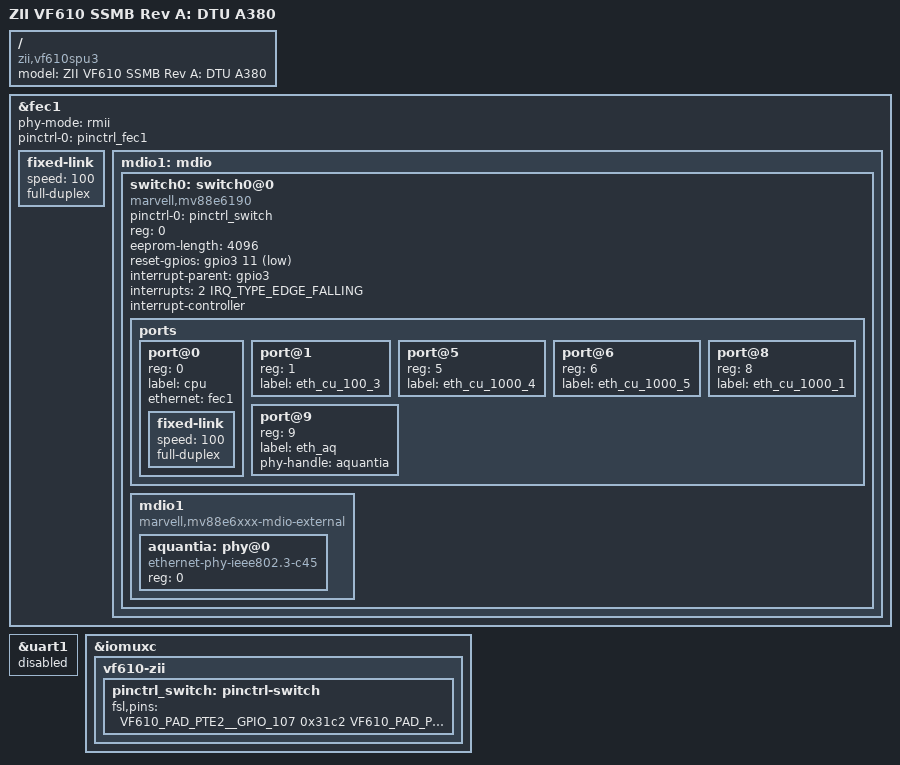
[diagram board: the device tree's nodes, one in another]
/*
 * Copyright (C) 2015, 2016 Zodiac Inflight Innovations
 *
 * Based on an original 'vf610-twr.dts' which is Copyright 2015,
 * Freescale Semiconductor, Inc.
 *
 * This file is dual-licensed: you can use it either under the terms
 * of the GPL or the X11 license, at your option. Note that this dual
 * licensing only applies to this file, and not this project as a
 * whole.
 *
 *  a) This file is free software; you can redistribute it and/or
 *     modify it under the terms of the GNU General Public License
 *     version 2 as published by the Free Software Foundation.
 *
 *     This file is distributed in the hope that it will be useful
 *     but WITHOUT ANY WARRANTY; without even the implied warranty of
 *     MERCHANTABILITY or FITNESS FOR A PARTICULAR PURPOSE.  See the
 *     GNU General Public License for more details.
 *
 * Or, alternatively
 *
 *  b) Permission is hereby granted, free of charge, to any person
 *     obtaining a copy of this software and associated documentation
 *     files (the "Software"), to deal in the Software without
 *     restriction, including without limitation the rights to use
 *     copy, modify, merge, publish, distribute, sublicense, and/or
 *     sell copies of the Software, and to permit persons to whom the
 *     Software is furnished to do so, subject to the following
 *     conditions:
 *
 *     The above copyright notice and this permission notice shall be
 *     included in all copies or substantial portions of the Software.
 *
 *     THE SOFTWARE IS PROVIDED , WITHOUT WARRANTY OF ANY KIND
 *     EXPRESS OR IMPLIED, INCLUDING BUT NOT LIMITED TO THE WARRANTIES
 *     OF MERCHANTABILITY, FITNESS FOR A PARTICULAR PURPOSE AND
 *     NONINFRINGEMENT. IN NO EVENT SHALL THE AUTHORS OR COPYRIGHT
 *     HOLDERS BE LIABLE FOR ANY CLAIM, DAMAGES OR OTHER LIABILITY
 *     WHETHER IN AN ACTION OF CONTRACT, TORT OR OTHERWISE, ARISING
 *     FROM, OUT OF OR IN CONNECTION WITH THE SOFTWARE OR THE USE OR
 *     OTHER DEALINGS IN THE SOFTWARE.
 */

/dts-v1/;
#include "vf610.dtsi"
#include "vf610-zii-ssmb.dtsi"


/ {
	model = "ZII VF610 SSMB Rev A: DTU A380";
	compatible = "zii,vf610spu3", "fsl,vf610";
};


&fec1 {
	phy-mode = "rmii";
	pinctrl-names = "default";
	pinctrl-0 = <&pinctrl_fec1>;
	status = "okay";

	fixed-link {
		   speed = <100>;
		   full-duplex;
	};

	mdio1: mdio {
		#address-cells = <1>;
		#size-cells = <0>;
		status = "okay";

		switch0: switch0@0 {
			compatible = "marvell,mv88e6190";
			pinctrl-0 = <&pinctrl_switch>;
			pinctrl-names = "default";
			#address-cells = <1>;
			#size-cells = <0>;
			reg = <0>;
			eeprom-length = <4096>;
			reset-gpios = <&gpio3 11 GPIO_ACTIVE_LOW>;
			interrupt-parent = <&gpio3>;
			interrupts = <2 IRQ_TYPE_EDGE_FALLING>;
			interrupt-controller;

			ports {
				#address-cells = <1>;
				#size-cells = <0>;
				port@0 {
					reg = <0>;
					label = "cpu";
					ethernet = <&fec1>;
					fixed-link {
						speed = <100>;
						full-duplex;
					};
				};
				port@1 {
					reg = <1>;
					label = "eth_cu_100_3";
				};

				port@5 {
					reg = <5>;
					label = "eth_cu_1000_4";
				};

				port@6 {
					reg = <6>;
					label = "eth_cu_1000_5";
				};

				/* hardware-disabled in flavour of port9 */
				//port@7 {
				//	reg = <7>;
				//	label = "eth_cu_100_2";
				//};

				port@8 {
					reg = <8>;
					label = "eth_cu_1000_1";
				};

				port@9 {
					reg = <9>;
					label = "eth_aq";
					phy-handle = <&aquantia>;
				};
			};

			mdio1 {
				compatible = "marvell,mv88e6xxx-mdio-external";
				#address-cells = <1>;
				#size-cells = <0>;

				aquantia: phy@0 {
					compatible = "ethernet-phy-ieee802.3-c45";
					reg = <0>;
				};
			};
		};
	};
};

/* UART1 pins are used as GPIO */
&uart1 {
	status = "disabled";
};

&iomuxc {
	vf610-zii {
		pinctrl_switch: pinctrl-switch {
			fsl,pins = <
				/* switch reset */
				VF610_PAD_PTE2__GPIO_107	0x31c2
				/* switch interrupt */
				VF610_PAD_PTB28__GPIO_98	0x0001
			>;
		};
	};
};
